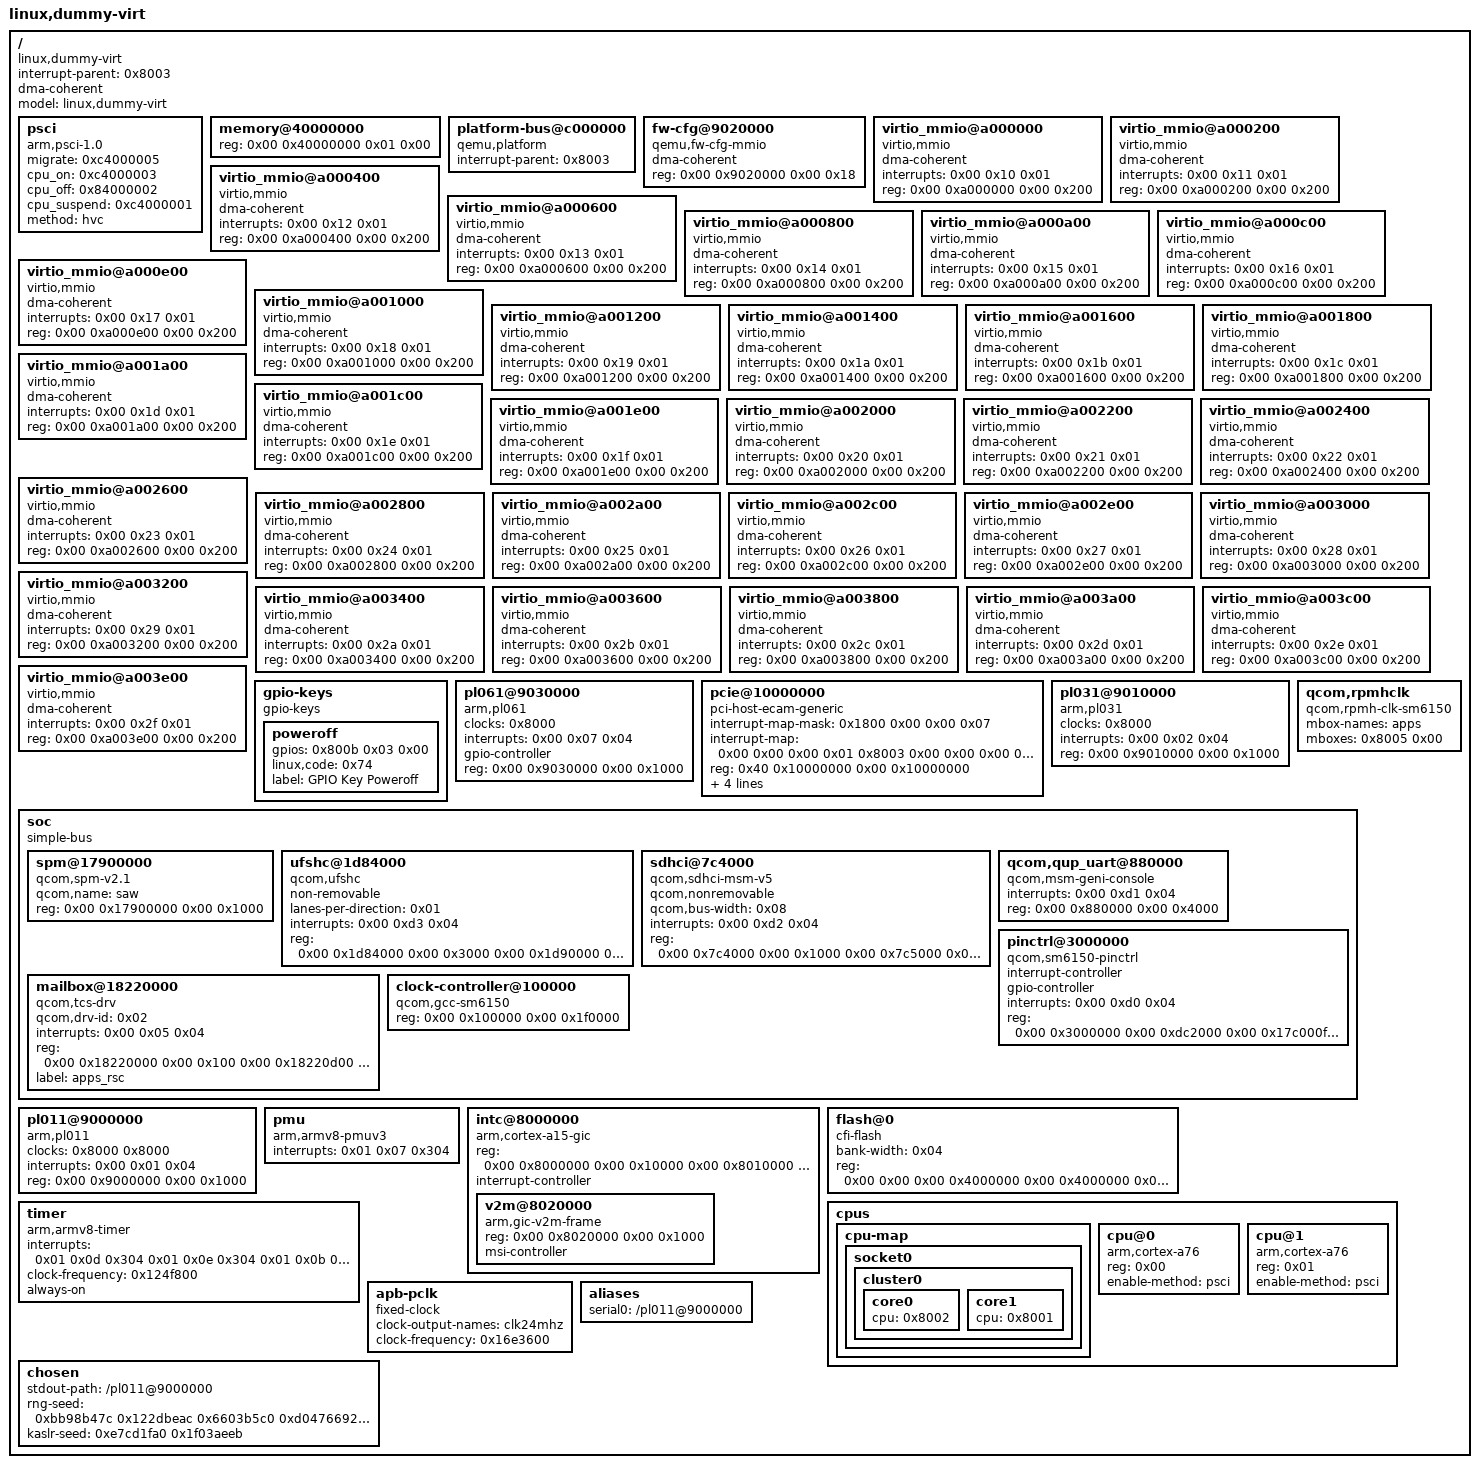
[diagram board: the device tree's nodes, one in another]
/dts-v1/;

/ {
	interrupt-parent = <0x8003>;
	dma-coherent;
	model = "linux,dummy-virt";
	#size-cells = <0x02>;
	#address-cells = <0x02>;
	compatible = "linux,dummy-virt";

	psci {
		migrate = <0xc4000005>;
		cpu_on = <0xc4000003>;
		cpu_off = <0x84000002>;
		cpu_suspend = <0xc4000001>;
		method = "hvc";
		compatible = "arm,psci-1.0", "arm,psci-0.2", "arm,psci";
	};

	memory@40000000 {
		reg = <0x00 0x40000000 0x01 0x00>;
		device_type = "memory";
	};

	platform-bus@c000000 {
		interrupt-parent = <0x8003>;
		ranges = <0x00 0x00 0xc000000 0x2000000>;
		#address-cells = <0x01>;
		#size-cells = <0x01>;
		compatible = "qemu,platform", "simple-bus";
	};

	fw-cfg@9020000 {
		dma-coherent;
		reg = <0x00 0x9020000 0x00 0x18>;
		compatible = "qemu,fw-cfg-mmio";
	};

	virtio_mmio@a000000 {
		dma-coherent;
		interrupts = <0x00 0x10 0x01>;
		reg = <0x00 0xa000000 0x00 0x200>;
		compatible = "virtio,mmio";
	};

	virtio_mmio@a000200 {
		dma-coherent;
		interrupts = <0x00 0x11 0x01>;
		reg = <0x00 0xa000200 0x00 0x200>;
		compatible = "virtio,mmio";
	};

	virtio_mmio@a000400 {
		dma-coherent;
		interrupts = <0x00 0x12 0x01>;
		reg = <0x00 0xa000400 0x00 0x200>;
		compatible = "virtio,mmio";
	};

	virtio_mmio@a000600 {
		dma-coherent;
		interrupts = <0x00 0x13 0x01>;
		reg = <0x00 0xa000600 0x00 0x200>;
		compatible = "virtio,mmio";
	};

	virtio_mmio@a000800 {
		dma-coherent;
		interrupts = <0x00 0x14 0x01>;
		reg = <0x00 0xa000800 0x00 0x200>;
		compatible = "virtio,mmio";
	};

	virtio_mmio@a000a00 {
		dma-coherent;
		interrupts = <0x00 0x15 0x01>;
		reg = <0x00 0xa000a00 0x00 0x200>;
		compatible = "virtio,mmio";
	};

	virtio_mmio@a000c00 {
		dma-coherent;
		interrupts = <0x00 0x16 0x01>;
		reg = <0x00 0xa000c00 0x00 0x200>;
		compatible = "virtio,mmio";
	};

	virtio_mmio@a000e00 {
		dma-coherent;
		interrupts = <0x00 0x17 0x01>;
		reg = <0x00 0xa000e00 0x00 0x200>;
		compatible = "virtio,mmio";
	};

	virtio_mmio@a001000 {
		dma-coherent;
		interrupts = <0x00 0x18 0x01>;
		reg = <0x00 0xa001000 0x00 0x200>;
		compatible = "virtio,mmio";
	};

	virtio_mmio@a001200 {
		dma-coherent;
		interrupts = <0x00 0x19 0x01>;
		reg = <0x00 0xa001200 0x00 0x200>;
		compatible = "virtio,mmio";
	};

	virtio_mmio@a001400 {
		dma-coherent;
		interrupts = <0x00 0x1a 0x01>;
		reg = <0x00 0xa001400 0x00 0x200>;
		compatible = "virtio,mmio";
	};

	virtio_mmio@a001600 {
		dma-coherent;
		interrupts = <0x00 0x1b 0x01>;
		reg = <0x00 0xa001600 0x00 0x200>;
		compatible = "virtio,mmio";
	};

	virtio_mmio@a001800 {
		dma-coherent;
		interrupts = <0x00 0x1c 0x01>;
		reg = <0x00 0xa001800 0x00 0x200>;
		compatible = "virtio,mmio";
	};

	virtio_mmio@a001a00 {
		dma-coherent;
		interrupts = <0x00 0x1d 0x01>;
		reg = <0x00 0xa001a00 0x00 0x200>;
		compatible = "virtio,mmio";
	};

	virtio_mmio@a001c00 {
		dma-coherent;
		interrupts = <0x00 0x1e 0x01>;
		reg = <0x00 0xa001c00 0x00 0x200>;
		compatible = "virtio,mmio";
	};

	virtio_mmio@a001e00 {
		dma-coherent;
		interrupts = <0x00 0x1f 0x01>;
		reg = <0x00 0xa001e00 0x00 0x200>;
		compatible = "virtio,mmio";
	};

	virtio_mmio@a002000 {
		dma-coherent;
		interrupts = <0x00 0x20 0x01>;
		reg = <0x00 0xa002000 0x00 0x200>;
		compatible = "virtio,mmio";
	};

	virtio_mmio@a002200 {
		dma-coherent;
		interrupts = <0x00 0x21 0x01>;
		reg = <0x00 0xa002200 0x00 0x200>;
		compatible = "virtio,mmio";
	};

	virtio_mmio@a002400 {
		dma-coherent;
		interrupts = <0x00 0x22 0x01>;
		reg = <0x00 0xa002400 0x00 0x200>;
		compatible = "virtio,mmio";
	};

	virtio_mmio@a002600 {
		dma-coherent;
		interrupts = <0x00 0x23 0x01>;
		reg = <0x00 0xa002600 0x00 0x200>;
		compatible = "virtio,mmio";
	};

	virtio_mmio@a002800 {
		dma-coherent;
		interrupts = <0x00 0x24 0x01>;
		reg = <0x00 0xa002800 0x00 0x200>;
		compatible = "virtio,mmio";
	};

	virtio_mmio@a002a00 {
		dma-coherent;
		interrupts = <0x00 0x25 0x01>;
		reg = <0x00 0xa002a00 0x00 0x200>;
		compatible = "virtio,mmio";
	};

	virtio_mmio@a002c00 {
		dma-coherent;
		interrupts = <0x00 0x26 0x01>;
		reg = <0x00 0xa002c00 0x00 0x200>;
		compatible = "virtio,mmio";
	};

	virtio_mmio@a002e00 {
		dma-coherent;
		interrupts = <0x00 0x27 0x01>;
		reg = <0x00 0xa002e00 0x00 0x200>;
		compatible = "virtio,mmio";
	};

	virtio_mmio@a003000 {
		dma-coherent;
		interrupts = <0x00 0x28 0x01>;
		reg = <0x00 0xa003000 0x00 0x200>;
		compatible = "virtio,mmio";
	};

	virtio_mmio@a003200 {
		dma-coherent;
		interrupts = <0x00 0x29 0x01>;
		reg = <0x00 0xa003200 0x00 0x200>;
		compatible = "virtio,mmio";
	};

	virtio_mmio@a003400 {
		dma-coherent;
		interrupts = <0x00 0x2a 0x01>;
		reg = <0x00 0xa003400 0x00 0x200>;
		compatible = "virtio,mmio";
	};

	virtio_mmio@a003600 {
		dma-coherent;
		interrupts = <0x00 0x2b 0x01>;
		reg = <0x00 0xa003600 0x00 0x200>;
		compatible = "virtio,mmio";
	};

	virtio_mmio@a003800 {
		dma-coherent;
		interrupts = <0x00 0x2c 0x01>;
		reg = <0x00 0xa003800 0x00 0x200>;
		compatible = "virtio,mmio";
	};

	virtio_mmio@a003a00 {
		dma-coherent;
		interrupts = <0x00 0x2d 0x01>;
		reg = <0x00 0xa003a00 0x00 0x200>;
		compatible = "virtio,mmio";
	};

	virtio_mmio@a003c00 {
		dma-coherent;
		interrupts = <0x00 0x2e 0x01>;
		reg = <0x00 0xa003c00 0x00 0x200>;
		compatible = "virtio,mmio";
	};

	virtio_mmio@a003e00 {
		dma-coherent;
		interrupts = <0x00 0x2f 0x01>;
		reg = <0x00 0xa003e00 0x00 0x200>;
		compatible = "virtio,mmio";
	};

	gpio-keys {
		compatible = "gpio-keys";

		poweroff {
			gpios = <0x800b 0x03 0x00>;
			linux,code = <0x74>;
			label = "GPIO Key Poweroff";
		};
	};

	pl061@9030000 {
		phandle = <0x800b>;
		clock-names = "apb_pclk";
		clocks = <0x8000>;
		interrupts = <0x00 0x07 0x04>;
		gpio-controller;
		#gpio-cells = <0x02>;
		compatible = "arm,pl061", "arm,primecell";
		reg = <0x00 0x9030000 0x00 0x1000>;
	};

	pcie@10000000 {
		interrupt-map-mask = <0x1800 0x00 0x00 0x07>;
		interrupt-map = <0x00 0x00 0x00 0x01 0x8003 0x00 0x00 0x00 0x03 0x04 0x00 0x00 0x00 0x02 0x8003 0x00 0x00 0x00 0x04 0x04 0x00 0x00 0x00 0x03 0x8003 0x00 0x00 0x00 0x05 0x04 0x00 0x00 0x00 0x04 0x8003 0x00 0x00 0x00 0x06 0x04 0x800 0x00 0x00 0x01 0x8003 0x00 0x00 0x00 0x04 0x04 0x800 0x00 0x00 0x02 0x8003 0x00 0x00 0x00 0x05 0x04 0x800 0x00 0x00 0x03 0x8003 0x00 0x00 0x00 0x06 0x04 0x800 0x00 0x00 0x04 0x8003 0x00 0x00 0x00 0x03 0x04 0x1000 0x00 0x00 0x01 0x8003 0x00 0x00 0x00 0x05 0x04 0x1000 0x00 0x00 0x02 0x8003 0x00 0x00 0x00 0x06 0x04 0x1000 0x00 0x00 0x03 0x8003 0x00 0x00 0x00 0x03 0x04 0x1000 0x00 0x00 0x04 0x8003 0x00 0x00 0x00 0x04 0x04 0x1800 0x00 0x00 0x01 0x8003 0x00 0x00 0x00 0x06 0x04 0x1800 0x00 0x00 0x02 0x8003 0x00 0x00 0x00 0x03 0x04 0x1800 0x00 0x00 0x03 0x8003 0x00 0x00 0x00 0x04 0x04 0x1800 0x00 0x00 0x04 0x8003 0x00 0x00 0x00 0x05 0x04>;
		#interrupt-cells = <0x01>;
		ranges = <0x1000000 0x00 0x00 0x00 0x3eff0000 0x00 0x10000 0x2000000 0x00 0x10000000 0x00 0x10000000 0x00 0x2eff0000 0x3000000 0x80 0x00 0x80 0x00 0x80 0x00>;
		reg = <0x40 0x10000000 0x00 0x10000000>;
		msi-map = <0x00 0x8004 0x00 0x10000>;
		dma-coherent;
		bus-range = <0x00 0xff>;
		linux,pci-domain = <0x00>;
		#size-cells = <0x02>;
		#address-cells = <0x03>;
		device_type = "pci";
		compatible = "pci-host-ecam-generic";
	};

	pl031@9010000 {
		clock-names = "apb_pclk";
		clocks = <0x8000>;
		interrupts = <0x00 0x02 0x04>;
		reg = <0x00 0x9010000 0x00 0x1000>;
		compatible = "arm,pl031", "arm,primecell";
	};

	qcom,rpmhclk {
		#clock-cells = <0x01>;
		mbox-names = "apps";
		mboxes = <0x8005 0x00>;
		compatible = "qcom,rpmh-clk-sm6150";
	};

	soc {
		ranges;
		#size-cells = <0x02>;
		#address-cells = <0x02>;
		compatible = "simple-bus";

		spm@17900000 {
			phandle = <0x800a>;
			qcom,name = "saw";
			reg = <0x00 0x17900000 0x00 0x1000>;
			compatible = "qcom,spm-v2.1";
		};

		ufshc@1d84000 {
			phandle = <0x8009>;
			non-removable;
			lanes-per-direction = <0x01>;
			interrupts = <0x00 0xd3 0x04>;
			reg-names = "ufs_mem";
			reg = <0x00 0x1d84000 0x00 0x3000 0x00 0x1d90000 0x00 0x8000>;
			compatible = "qcom,ufshc";
		};

		sdhci@7c4000 {
			phandle = <0x8008>;
			qcom,nonremovable;
			qcom,bus-width = <0x08>;
			interrupts = <0x00 0xd2 0x04>;
			reg-names = "hc_mem";
			reg = <0x00 0x7c4000 0x00 0x1000 0x00 0x7c5000 0x00 0x1000 0x00 0x7c8000 0x00 0x8000>;
			compatible = "qcom,sdhci-msm-v5";
		};

		qcom,qup_uart@880000 {
			phandle = <0x8007>;
			interrupts = <0x00 0xd1 0x04>;
			reg-names = "se_phys";
			reg = <0x00 0x880000 0x00 0x4000>;
			compatible = "qcom,msm-geni-console";
		};

		pinctrl@3000000 {
			phandle = <0x8006>;
			#interrupt-cells = <0x02>;
			interrupt-controller;
			#gpio-cells = <0x02>;
			gpio-controller;
			interrupts = <0x00 0xd0 0x04>;
			reg = <0x00 0x3000000 0x00 0xdc2000 0x00 0x17c000f0 0x00 0x50>;
			compatible = "qcom,sm6150-pinctrl";
		};

		mailbox@18220000 {
			phandle = <0x8005>;
			qcom,drv-id = <0x02>;
			#mbox-cells = <0x01>;
			interrupts = <0x00 0x05 0x04>;
			reg = <0x00 0x18220000 0x00 0x100 0x00 0x18220d00 0x00 0x3000>;
			label = "apps_rsc";
			compatible = "qcom,tcs-drv";
		};

		clock-controller@100000 {
			#power-domain-cells = <0x01>;
			#reset-cells = <0x01>;
			#clock-cells = <0x01>;
			reg = <0x00 0x100000 0x00 0x1f0000>;
			compatible = "qcom,gcc-sm6150", "syscon";
		};
	};

	pl011@9000000 {
		clock-names = "uartclk", "apb_pclk";
		clocks = <0x8000 0x8000>;
		interrupts = <0x00 0x01 0x04>;
		reg = <0x00 0x9000000 0x00 0x1000>;
		compatible = "arm,pl011", "arm,primecell";
	};

	pmu {
		interrupts = <0x01 0x07 0x304>;
		compatible = "arm,armv8-pmuv3";
	};

	intc@8000000 {
		phandle = <0x8003>;
		reg = <0x00 0x8000000 0x00 0x10000 0x00 0x8010000 0x00 0x10000>;
		compatible = "arm,cortex-a15-gic";
		ranges;
		#size-cells = <0x02>;
		#address-cells = <0x02>;
		interrupt-controller;
		#interrupt-cells = <0x03>;

		v2m@8020000 {
			phandle = <0x8004>;
			reg = <0x00 0x8020000 0x00 0x1000>;
			msi-controller;
			compatible = "arm,gic-v2m-frame";
		};
	};

	flash@0 {
		bank-width = <0x04>;
		reg = <0x00 0x00 0x00 0x4000000 0x00 0x4000000 0x00 0x4000000>;
		compatible = "cfi-flash";
	};

	cpus {
		#size-cells = <0x00>;
		#address-cells = <0x01>;

		cpu-map {

			socket0 {

				cluster0 {

					core0 {
						cpu = <0x8002>;
					};

					core1 {
						cpu = <0x8001>;
					};
				};
			};
		};

		cpu@0 {
			phandle = <0x8002>;
			reg = <0x00>;
			enable-method = "psci";
			compatible = "arm,cortex-a76";
			device_type = "cpu";
		};

		cpu@1 {
			phandle = <0x8001>;
			reg = <0x01>;
			enable-method = "psci";
			compatible = "arm,cortex-a76";
			device_type = "cpu";
		};
	};

	timer {
		interrupts = <0x01 0x0d 0x304 0x01 0x0e 0x304 0x01 0x0b 0x304 0x01 0x0a 0x304>;
		clock-frequency = <0x124f800>;
		always-on;
		compatible = "arm,armv8-timer", "arm,armv7-timer";
	};

	apb-pclk {
		phandle = <0x8000>;
		clock-output-names = "clk24mhz";
		clock-frequency = <0x16e3600>;
		#clock-cells = <0x00>;
		compatible = "fixed-clock";
	};

	aliases {
		serial0 = "/pl011@9000000";
	};

	chosen {
		stdout-path = "/pl011@9000000";
		rng-seed = <0xbb98b47c 0x122dbeac 0x6603b5c0 0xd0476692 0xe37fa246 0xe8d7868d 0x584f97b0 0x1da7550>;
		kaslr-seed = <0xe7cd1fa0 0x1f03aeeb>;
	};
};
